# SC000 register map
Vendor: Arm Ltd.; Series: ARMv6-M; File version: 1.0.0
CPU: SC000 r0p0, little endian, MPU, no FPU, 2 interrupt priority bits
Registers are 32-bit, read-write, reset 0x0 unless marked. A register's access mark holds for its fields unless they carry their own. Offsets are from the block's base; [hi:lo] are bit positions; {n}, {i} and the like mark numbered series.

## DWT — Data Watchpoint and Trace unit: cycle counter and profiling counters, PC sampling, exception trace, and address/data comparators that raise watchpoints (halt or DebugMonitor), trigger the ETM/CTI or emit data trace. Needs DEMCR.TRCENA = 1.
Base 0xE0001000
0x00 CTRL ro — DWT Control Register: cycle counter, PC sampling, exception trace and profiling event enables; read-only capability bits (NUMCOMP, NOCYCCNT...) in the top byte.
  [31:28] NUMCOMP — Number of comparators implemented (0-15; 4 on most Cortex-M3/M4/M7/M33 devices). Read-only.
0x1C PCSR ro — Program Counter Sample Register: the address of a recently executed instruction - read repeatedly by a debugger for non-intrusive statistical profiling. 0xFFFFFFFF when halted.
  [31:0] EIASAMPLE — Sampled instruction address.
{0x20+0x10*i} COMP{i} (i=0..1) — Comparator Register n: the address (or data value / cycle count) that comparator n matches against, as configured in FUNCTIONn.
  [31:0] COMP — Reference address for watchpoint comparator n.
{0x24+0x10*i} MASK{i} (i=0..1) — Mask Register n (ARMv7-M): number of low address bits ignored by comparator n, making it match a power-of-two range.
  [4:0] MASK — Log2 of the number of low address bits ignored by the comparator (0 = exact match, 4 = 16-byte range ...). The maximum supported value is found by writing all ones and reading back.
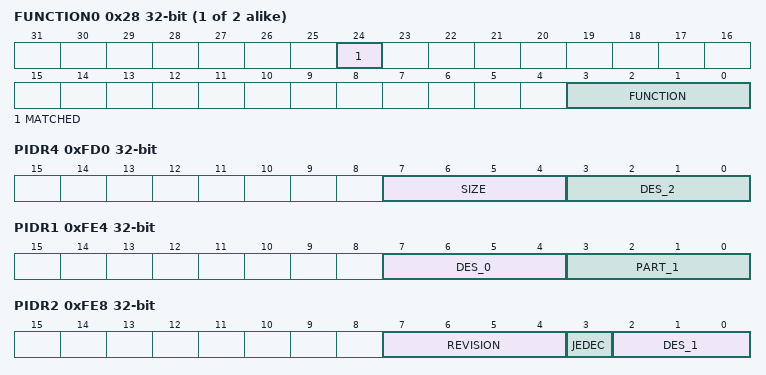
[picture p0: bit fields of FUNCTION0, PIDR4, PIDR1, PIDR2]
{0x28+0x10*i} FUNCTION{i} (i=0..1) — Function Register n: what comparator n compares (instruction address, data address, data value, cycle count) and what happens on a match (watchpoint debug event, trace packet, CMPMATCH trigger). MATCHED reports a hit.
  [24] MATCHED — The comparator matched since this register was last read. Cleared on read.
  [3:0] FUNCTION — ARMv7-M comparator function: 0 disabled; 1 emit PC sample on match, 2 emit data value, 3 emit PC and data value; 4 watchpoint on instruction fetch (PC), 5 watchpoint on read, 6 watchpoint on write, 7 watchpoint on read or write; 8-15 ETM trigger / data trace variants. With CYCMATCH: 1 = event, 4 = watchpoint on cycle count match.
0xFD0 PIDR4 ro — Peripheral Identification Register 4: JEP106 continuation code and component size.
  [7:4] SIZE — Log2 of the number of 4 KB blocks the component occupies (0 = one block).
  [3:0] DES_2 — JEP106 continuation code of the designer (Arm: 0x4).
{0xFC0+4i} PIDR{i} ro (i=5..7) — Peripheral Identification Register {i} (reserved, reads as zero).
0xFE0 PIDR0 ro — Peripheral Identification Register 0: part number bits [7:0].
  [7:0] PART_0 — Part number bits [7:0].
0xFE4 PIDR1 ro — Peripheral Identification Register 1: part number bits [11:8] and designer bits [3:0].
  [7:4] DES_0 — JEP106 identity code bits [3:0] of the designer.
  [3:0] PART_1 — Part number bits [11:8].
0xFE8 PIDR2 ro — Peripheral Identification Register 2: designer bits [6:4], JEDEC flag and revision.
  [7:4] REVISION — Component major revision.
  [3] JEDEC — Always 1: the designer ID is a JEDEC JEP106 code.
  [2:0] DES_1 — JEP106 identity code bits [6:4] of the designer.
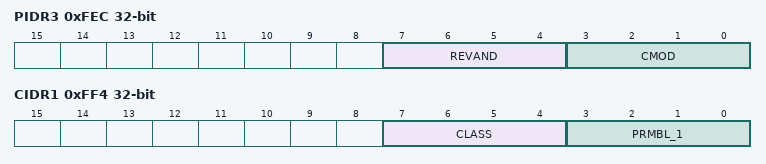
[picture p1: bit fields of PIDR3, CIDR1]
0xFEC PIDR3 ro — Peripheral Identification Register 3: customer modified and minor revision.
  [7:4] REVAND — Minor revision (metal fix) number.
  [3:0] CMOD — Customer Modified: 0 if the component has not been modified by the integrator.
0xFF0 CIDR0 ro — Component Identification Register 0: preamble byte 0 (0x0D).
  [7:0] PRMBL_0 — Preamble, reads as 0x0D.
0xFF4 CIDR1 ro — Component Identification Register 1: component class and preamble.
  [7:4] CLASS — Component class: 0x1 ROM table, 0x9 CoreSight component, 0xE generic IP, 0xF CoreLink/PrimeCell.
  [3:0] PRMBL_1 — Preamble, reads as 0x0.
0xFF8 CIDR2 ro — Component Identification Register 2: preamble byte 2 (0x05).
  [7:0] PRMBL_2 — Preamble, reads as 0x05.
0xFFC CIDR3 ro — Component Identification Register 3: preamble byte 3 (0xB1).
  [7:0] PRMBL_3 — Preamble, reads as 0xB1.

## BPU — Breakpoint Unit (Flash Patch and Breakpoint unit FPBv2 on STAR-MC1): up to eight hardware instruction breakpoint comparators.
Base 0xE0002000
Registers as DWT, without CTRL, PCSR, COMP*, MASK*, FUNCTION*; these are added or differ:
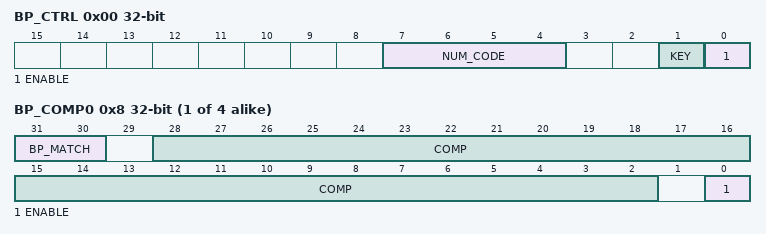
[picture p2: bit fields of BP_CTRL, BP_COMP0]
0x00 BP_CTRL — Breakpoint Control Register: enable and number of comparators. Writes must set KEY.
  [7:4] NUM_CODE — Number of breakpoint comparators implemented (0 to 4).
  [1] KEY — Write 1 to enable writes to BP_CTRL; reads as zero.
  [0] ENABLE — Breakpoint unit enable. Reset value 0.
{0x8+4i} BP_COMP{i} (i=0..3) — Breakpoint Comparator Register n: instruction address to break on (code region 0x00000000-0x1FFFFFFF, word aligned) and which halfword.
  [31:30] BP_MATCH — Halfword to match: 0 no breakpoint, 1 lower halfword (bits[1:0] = 00), 2 upper halfword (bits[1:0] = 10), 3 both.
  [28:2] COMP — Bits [28:2] of the word address to compare.
  [0] ENABLE — Comparator enable.
